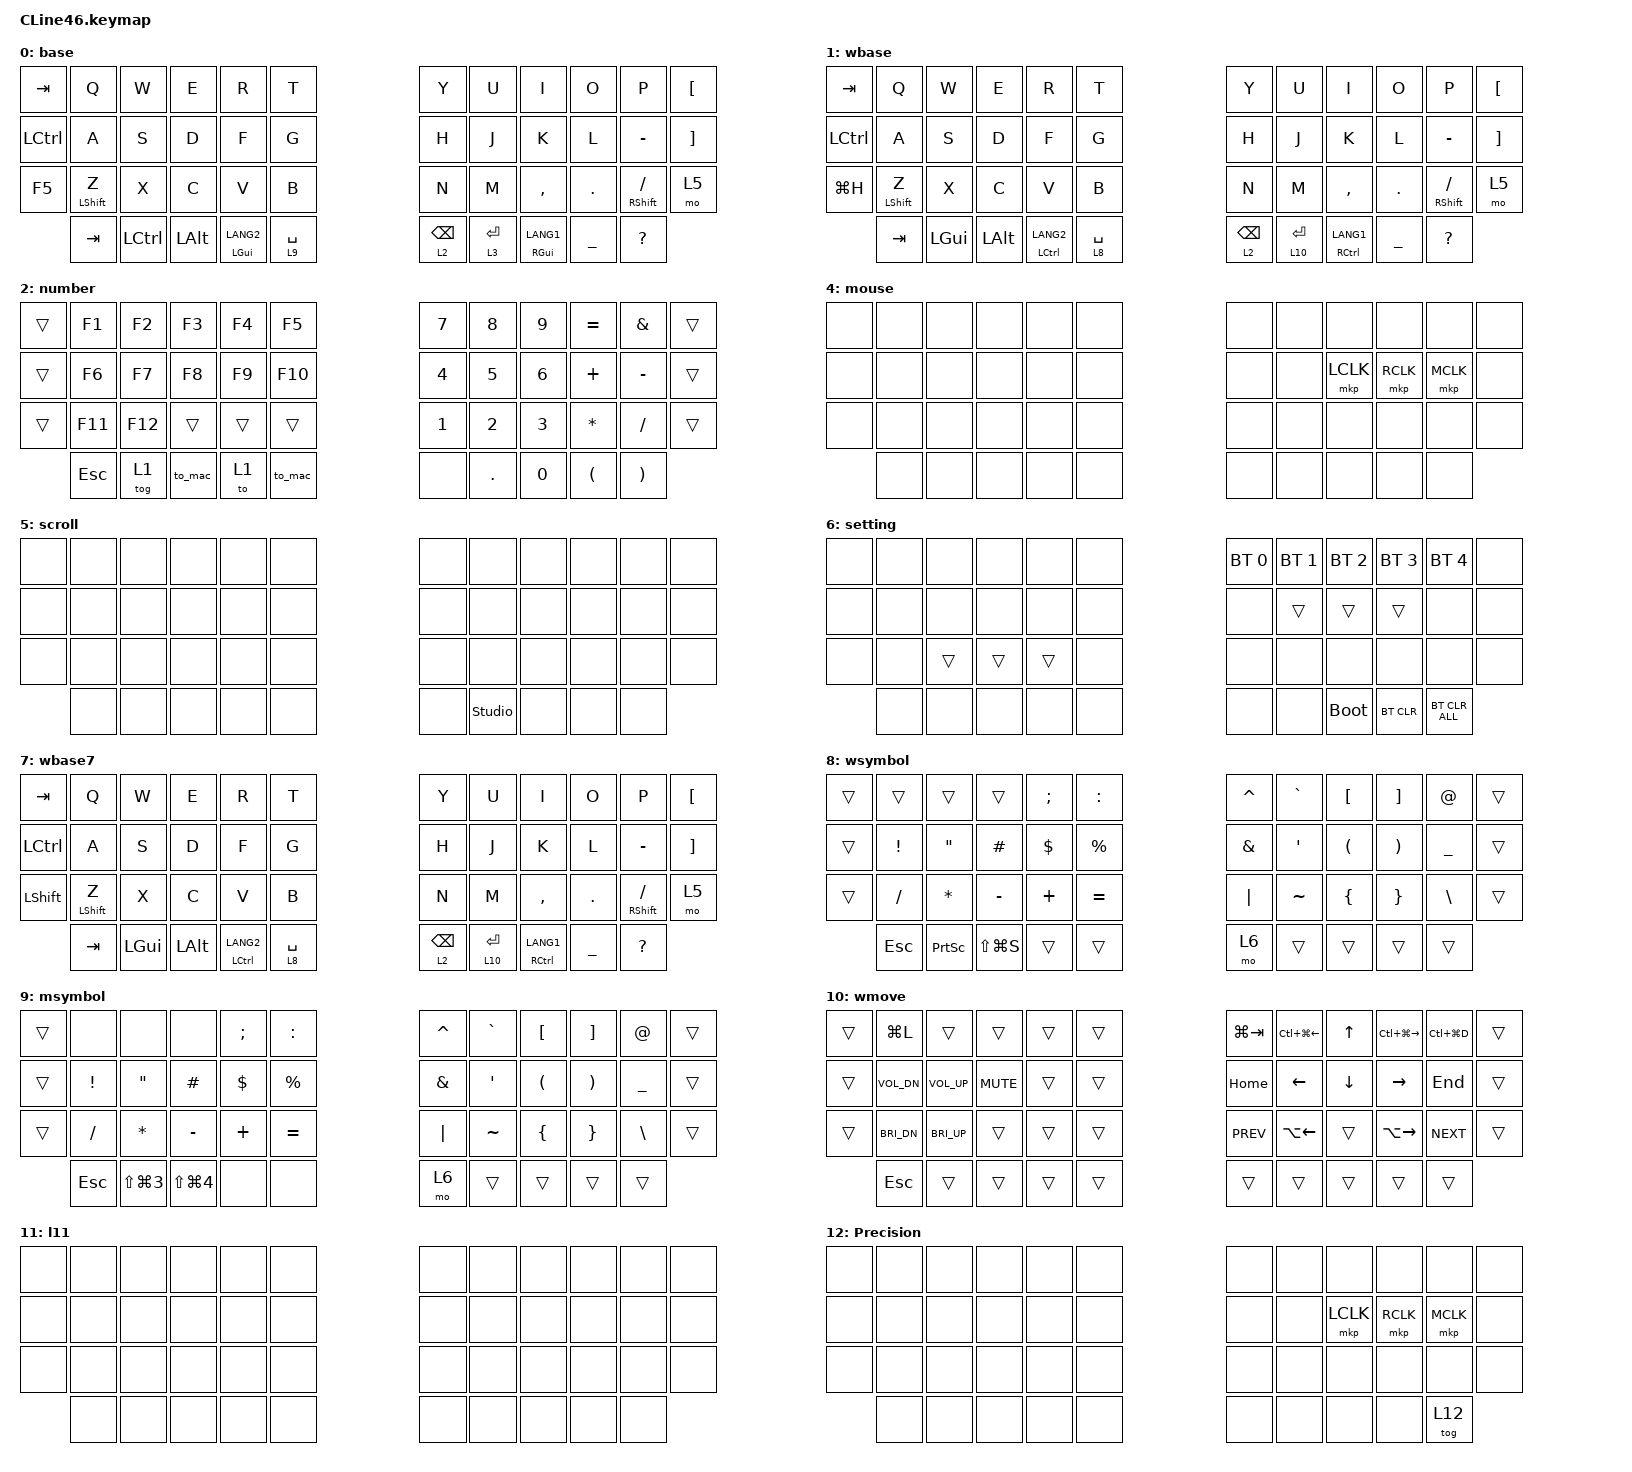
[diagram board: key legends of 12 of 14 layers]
#include <input/processors.dtsi>
#include <dt-bindings/zmk/input_transform.h>
#include <zephyr/dt-bindings/input/input-event-codes.h>
#include <behaviors.dtsi>
#include <dt-bindings/zmk/bt.h>
#include <dt-bindings/zmk/keys.h>
#include <dt-bindings/zmk/pointing.h>

// conductor-keymap 4.json (2026-07-24) 準拠
// レイヤー番号はConductorと完全一致: 0=base 1=wbase 2=number 3=move 4=mouse
// 5=scroll 6=setting 7=wbase(旧・未使用) 8=wsymbol 9=msymbol 10=wmove 11=(空) 12=Precision 13=Gesture

// Conductor実測値(2026-07-31 Timingタブ): ホールド判定=タップ優先 / Tapping Term 200ms / quick-tap 200ms
&mt {
    flavor = "tap-preferred";
    tapping-term-ms = <200>;
    quick-tap-ms = <200>;
};

// タップ→200ms以内に押し直して長押しでタップ側キーを連打（Conductor/QMKのquick tap相当）
// 例: BSPCをトントン→長押しで連続削除
&lt {
    flavor = "tap-preferred";
    tapping-term-ms = <200>;
    quick-tap-ms = <200>;
};

/ {
    combos {
        compatible = "zmk,combos";

        // K+L 同時押し → スクロールレイヤー(5)ホールド
        combo_scroll {
            bindings = <&mo 5>;
            key-positions = <20 21>;
            timeout-ms = <50>;
        };

        // Q+A+Z 同時押し → BTプロファイル3(予備枠)選択 ※Conductor仕様はBT5だが本機は0-3の4枠
        combo_pair {
            bindings = <&bt BT_SEL 3>;
            key-positions = <1 13 25>;
            timeout-ms = <50>;
        };

        // T+O+B 同時押し → ブートローダー(UF2書込モード)
        combo_boot {
            bindings = <&bootloader>;
            key-positions = <5 9 29>;
            timeout-ms = <50>;
        };

        // I+O 同時押し → Gestureレイヤー(13)ホールド
        combo_gesture {
            bindings = <&mo 13>;
            key-positions = <8 9>;
            timeout-ms = <50>;
        };

        // K+L+minus → ズーム(Conductorのピンチズーム相当: Cmd+スクロールで近似)
        combo_zoom {
            bindings = <&zoom_hold>;
            key-positions = <20 21 22>;
            timeout-ms = <50>;
        };
    };

    macros {
        // Cmd押しっぱなし+スクロールレイヤー(多くのMacアプリでズームになる)
        zoom_hold: zoom_hold {
            compatible = "zmk,behavior-macro";
            #binding-cells = <0>;
            bindings
                = <&macro_press &kp LGUI &mo 5>
                , <&macro_pause_for_release>
                , <&macro_release &kp LGUI &mo 5>;
        };

        to_layer_0: to_layer_0 {
            compatible = "zmk,behavior-macro-one-param";
            #binding-cells = <1>;
            bindings = <&to 0 &macro_param_1to1 &kp MACRO_PLACEHOLDER>;
            label = "TO_LAYER_0";
        };

        // どの状態からでも確実にMac(base)へ戻る: wbaseを一旦ONにしてからOFF
        to_mac: to_mac {
            compatible = "zmk,behavior-macro";
            #binding-cells = <0>;
            bindings = <&to 1 &tog 1>;
            label = "TO_MAC";
        };
    };

    behaviors {
        lt_to_layer_0: lt_to_layer_0 {
            compatible = "zmk,behavior-hold-tap";
            label = "LAYER_TAP_TO_0";
            bindings = <&mo>, <&to_layer_0>;

            #binding-cells = <2>;
            tapping-term-ms = <200>;
        };
    };

    keymap {
        compatible = "zmk,keymap";

        base {
            display-name = "base";
            bindings = <
&kp TAB     &kp Q         &kp W     &kp E     &kp R           &kp T                                      &kp Y    &kp U            &kp I      &kp O    &kp P              &kp LEFT_BRACKET
&kp LCTRL   &kp A         &kp S     &kp D     &kp F           &kp G                                      &kp H    &kp J            &kp K      &kp L    &kp MINUS          &kp RIGHT_BRACKET
&kp F5      &mt LSHIFT Z  &kp X     &kp C     &kp V           &kp B                                      &kp N    &kp M            &kp COMMA  &kp DOT  &mt RSHIFT SLASH   &mo 5
            &kp TAB       &kp LCTRL &kp LALT  &mt LGUI LANG2  &lt 9 SPACE   &lt 2 BSPC      &lt 3 RET    &mt RGUI LANG1                       &kp UNDER  &kp QMARK
            >;
        };

        wbase {
            display-name = "wbase";
            bindings = <
&kp TAB     &kp Q         &kp W     &kp E     &kp R            &kp T                                      &kp Y    &kp U            &kp I      &kp O    &kp P              &kp LEFT_BRACKET
&kp LCTRL   &kp A         &kp S     &kp D     &kp F            &kp G                                      &kp H    &kp J            &kp K      &kp L    &kp MINUS          &kp RIGHT_BRACKET
&kp LG(H)   &mt LSHIFT Z  &kp X     &kp C     &kp V            &kp B                                      &kp N    &kp M            &kp COMMA  &kp DOT  &mt RSHIFT SLASH   &mo 5
            &kp TAB       &kp LGUI  &kp LALT  &mt LCTRL LANG2  &lt 8 SPACE   &lt 2 BSPC      &lt 10 RET   &mt RCTRL LANG1                      &kp UNDER  &kp QMARK
            >;
        };

        number {
            display-name = "number";
            bindings = <
&trans   &kp F1    &kp F2    &kp F3   &kp F4   &kp F5                              &kp N7   &kp N8  &kp N9  &kp EQUAL  &kp AMPS   &trans
&trans   &kp F6    &kp F7    &kp F8   &kp F9   &kp F10                             &kp N4   &kp N5  &kp N6  &kp PLUS   &kp MINUS  &trans
&trans   &kp F11   &kp F12   &trans   &trans   &trans                              &kp N1   &kp N2  &kp N3  &kp STAR   &kp SLASH  &trans
         &kp ESC   &tog 1    &to_mac  &to 1    &to_mac  &none            &kp DOT   &kp N0                   &kp LPAR   &kp RPAR
            >;
        };

        move {
            display-name = "move";
            bindings = <
&trans   &kp LC(LG(Q))  &trans   &trans   &trans      &kp KP_N2                            &kp LC(UP)   &kp LC(LEFT)  &kp UP    &kp LC(RIGHT)  &kp LC(DOWN)  &trans
&trans   &kp C_VOL_DN   &kp C_VOL_UP &kp C_MUTE &trans     &kp KP_N1                            &kp LC(A)    &kp LEFT      &kp DOWN  &kp RIGHT      &kp LC(E)     &trans
&trans   &kp C_BRI_DN   &kp C_BRI_UP &trans   &trans      &kp KP_N0                            &kp C_PREV   &kp LG(LEFT)  &kp N1    &kp LG(RIGHT)  &kp C_NEXT    &trans
         &kp ESC        &none    &none    &none       &none       &none       &none        &kp LA(LC(LS(D)))                    &kp N0         &kp LA(LS(LG(SPACE)))
            >;
        };

        mouse {
            display-name = "mouse";
            bindings = <
&none   &none   &none   &none   &none   &none                          &none   &none      &none      &none      &none      &none
&none   &none   &none   &none   &none   &none                          &none   &none      &mkp LCLK  &mkp RCLK  &mkp MCLK  &none
&none   &none   &none   &none   &none   &none                          &none   &none      &none      &none      &none      &none
        &none   &none   &none   &none   &none   &none        &none     &none                         &none      &none
            >;
        };

        scroll {
            display-name = "scroll";
            bindings = <
&none   &none   &none   &none   &none   &none                          &none   &none      &none      &none      &none      &none
&none   &none   &none   &none   &none   &none                          &none   &none      &none      &none      &none      &none
&none   &none   &none   &none   &none   &none                          &none   &none      &none      &none      &none      &none
        &none   &none   &none   &none   &none   &none    &studio_unlock  &none                       &none      &none
            >;
        };

        setting {
            display-name = "setting";
            bindings = <
&none   &none   &none    &none    &none    &none                          &bt BT_SEL 0  &bt BT_SEL 1  &bt BT_SEL 2  &bt BT_SEL 3   &bt BT_SEL 4     &none
&none   &none   &none    &none    &none    &none                          &none         &trans        &trans        &trans         &none            &none
&none   &none   &trans   &trans   &trans   &none                          &none         &none         &none         &none          &none            &none
        &none   &none    &none    &none    &none    &none      &none      &bootloader                               &bt BT_CLR     &bt BT_CLR_ALL
            >;
        };

        wbase_old {
            display-name = "wbase7";
            bindings = <
&kp TAB     &kp Q         &kp W     &kp E     &kp R            &kp T                                      &kp Y    &kp U            &kp I      &kp O    &kp P              &kp LEFT_BRACKET
&kp LCTRL   &kp A         &kp S     &kp D     &kp F            &kp G                                      &kp H    &kp J            &kp K      &kp L    &kp MINUS          &kp RIGHT_BRACKET
&kp LSHIFT  &mt LSHIFT Z  &kp X     &kp C     &kp V            &kp B                                      &kp N    &kp M            &kp COMMA  &kp DOT  &mt RSHIFT SLASH   &mo 5
            &kp TAB       &kp LGUI  &kp LALT  &mt LCTRL LANG2  &lt 8 SPACE   &lt 2 BSPC      &lt 10 RET   &mt RCTRL LANG1                      &kp UNDER  &kp QMARK
            >;
        };

        wsymbol {
            display-name = "wsymbol";
            bindings = <
&trans   &trans           &trans           &trans         &kp SEMI     &kp COLON                             &kp CARET  &kp GRAVE  &kp LBKT  &kp RBKT  &kp AT_SIGN  &trans
&trans   &kp EXCL         &kp DQT          &kp HASH       &kp DOLLAR   &kp PRCNT                             &kp AMPS   &kp SQT    &kp LPAR  &kp RPAR  &kp UNDER    &trans
&trans   &kp SLASH        &kp STAR         &kp MINUS      &kp PLUS     &kp EQUAL                             &kp PIPE   &kp TILDE  &kp LBRC  &kp RBRC  &kp BSLH     &trans
         &kp ESC          &kp PSCRN        &kp LS(LG(S))  &trans       &trans       &mo 6         &trans     &trans                          &trans     &trans
            >;
        };

        msymbol {
            display-name = "msymbol";
            bindings = <
&trans   &none            &none            &none          &kp SEMI     &kp COLON                             &kp CARET  &kp GRAVE  &kp LBKT  &kp RBKT  &kp AT_SIGN  &trans
&trans   &kp EXCL         &kp DQT          &kp HASH       &kp DOLLAR   &kp PRCNT                             &kp AMPS   &kp SQT    &kp LPAR  &kp RPAR  &kp UNDER    &trans
&trans   &kp SLASH        &kp STAR         &kp MINUS      &kp PLUS     &kp EQUAL                             &kp PIPE   &kp TILDE  &kp LBRC  &kp RBRC  &kp BSLH     &trans
         &kp ESC          &kp LS(LG(N3))   &kp LS(LG(N4)) &none        &none        &mo 6         &trans     &trans                          &trans     &trans
            >;
        };

        wmove {
            display-name = "wmove";
            bindings = <
&trans   &kp LG(L)  &trans   &trans   &trans   &trans                            &kp LG(TAB)  &kp LC(LG(LEFT))  &kp UP    &kp LC(LG(RIGHT))  &kp LC(LG(D))  &trans
&trans   &kp C_VOL_DN &kp C_VOL_UP &kp C_MUTE &trans &trans                    &kp HOME     &kp LEFT          &kp DOWN  &kp RIGHT          &kp END        &trans
&trans   &kp C_BRI_DN &kp C_BRI_UP &trans   &trans   &trans                      &kp C_PREV   &kp LA(LEFT)      &trans    &kp LA(RIGHT)      &kp C_NEXT     &trans
         &kp ESC    &trans   &trans   &trans   &trans   &trans        &trans     &trans                                   &trans             &trans
            >;
        };

        unused11 {
            display-name = "l11";
            bindings = <
&none   &none   &none   &none   &none   &none                          &none   &none      &none      &none      &none      &none
&none   &none   &none   &none   &none   &none                          &none   &none      &none      &none      &none      &none
&none   &none   &none   &none   &none   &none                          &none   &none      &none      &none      &none      &none
        &none   &none   &none   &none   &none   &none        &none     &none                         &none      &none
            >;
        };

        precision {
            display-name = "Precision";
            bindings = <
&none   &none   &none   &none   &none   &none                          &none   &none      &none      &none      &none      &none
&none   &none   &none   &none   &none   &none                          &none   &none      &mkp LCLK  &mkp RCLK  &mkp MCLK  &none
&none   &none   &none   &none   &none   &none                          &none   &none      &none      &none      &none      &none
        &none   &none   &none   &none   &none   &none        &none     &none                         &none      &tog 12
            >;
        };

        gesture {
            display-name = "Gesture";
            bindings = <
&none   &none   &none   &none   &none   &none                          &none   &none          &kp LC(DOWN)  &none         &none   &none
&none   &none   &none   &none   &none   &none                          &none   &kp LC(RIGHT)  &none         &kp LC(LEFT)  &none   &none
&none   &none   &none   &none   &none   &none                          &none   &none          &kp LC(UP)    &none         &none   &none
        &none   &none   &none   &none   &none   &none        &none     &none                                &none         &none
            >;
        };
    };
};
